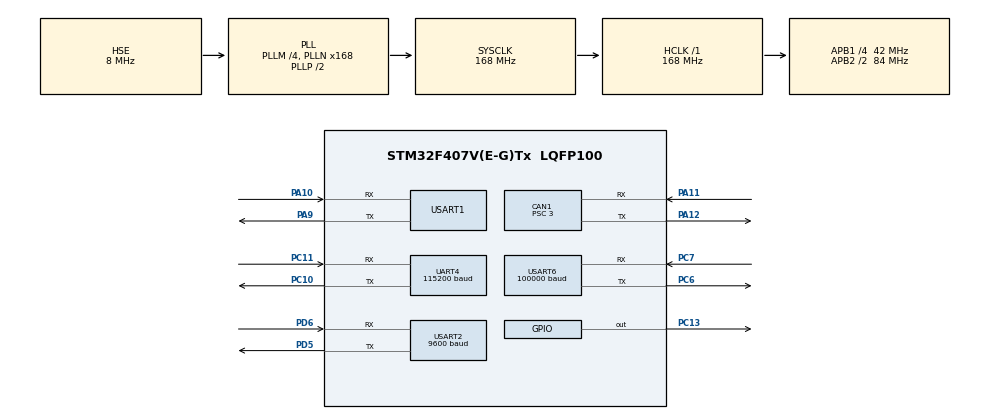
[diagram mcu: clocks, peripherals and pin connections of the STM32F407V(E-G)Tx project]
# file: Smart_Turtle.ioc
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CAN1.BS1=CAN_BS1_10TQ
CAN1.BS2=CAN_BS2_3TQ
CAN1.CalculateBaudRate=1000000
CAN1.CalculateTimeBit=1000
CAN1.CalculateTimeQuantum=71.42857142857143
CAN1.Prescaler=3
Dma.Request0=USART1_RX
Dma.Request1=USART1_TX
Dma.Request2=USART2_TX
Dma.Request3=USART2_RX
Dma.Request4=USART6_RX
Dma.Request5=USART6_TX
Dma.USART1_RX.0.Direction=DMA_PERIPH_TO_MEMORY
Dma.USART1_RX.0.FIFOMode=DMA_FIFOMODE_DISABLE
Dma.USART1_RX.0.Instance=DMA2_Stream2
Dma.USART1_RX.0.MemDataAlignment=DMA_MDATAALIGN_BYTE
Dma.USART1_RX.0.MemInc=DMA_MINC_ENABLE
Dma.USART1_RX.0.Mode=DMA_NORMAL
Dma.USART1_RX.0.PeriphDataAlignment=DMA_PDATAALIGN_BYTE
Dma.USART1_RX.0.PeriphInc=DMA_PINC_DISABLE
Dma.USART1_RX.0.Priority=DMA_PRIORITY_VERY_HIGH
Dma.USART1_TX.1.Direction=DMA_MEMORY_TO_PERIPH
Dma.USART1_TX.1.FIFOMode=DMA_FIFOMODE_DISABLE
Dma.USART1_TX.1.Instance=DMA2_Stream7
Dma.USART1_TX.1.MemDataAlignment=DMA_MDATAALIGN_BYTE
Dma.USART1_TX.1.MemInc=DMA_MINC_ENABLE
Dma.USART1_TX.1.Mode=DMA_NORMAL
Dma.USART1_TX.1.PeriphDataAlignment=DMA_PDATAALIGN_BYTE
Dma.USART1_TX.1.PeriphInc=DMA_PINC_DISABLE
Dma.USART1_TX.1.Priority=DMA_PRIORITY_VERY_HIGH
Dma.USART2_RX.3.Direction=DMA_PERIPH_TO_MEMORY
Dma.USART2_RX.3.FIFOMode=DMA_FIFOMODE_DISABLE
Dma.USART2_RX.3.Instance=DMA1_Stream5
Dma.USART2_RX.3.MemDataAlignment=DMA_MDATAALIGN_BYTE
Dma.USART2_RX.3.MemInc=DMA_MINC_ENABLE
Dma.USART2_RX.3.Mode=DMA_NORMAL
Dma.USART2_RX.3.PeriphDataAlignment=DMA_PDATAALIGN_BYTE
Dma.USART2_RX.3.PeriphInc=DMA_PINC_DISABLE
Dma.USART2_RX.3.Priority=DMA_PRIORITY_VERY_HIGH
Dma.USART2_TX.2.Direction=DMA_MEMORY_TO_PERIPH
Dma.USART2_TX.2.FIFOMode=DMA_FIFOMODE_DISABLE
Dma.USART2_TX.2.Instance=DMA1_Stream6
Dma.USART2_TX.2.MemDataAlignment=DMA_MDATAALIGN_BYTE
Dma.USART2_TX.2.MemInc=DMA_MINC_ENABLE
Dma.USART2_TX.2.Mode=DMA_NORMAL
Dma.USART2_TX.2.PeriphDataAlignment=DMA_PDATAALIGN_BYTE
Dma.USART2_TX.2.PeriphInc=DMA_PINC_DISABLE
Dma.USART2_TX.2.Priority=DMA_PRIORITY_VERY_HIGH
Dma.USART6_RX.4.Direction=DMA_PERIPH_TO_MEMORY
Dma.USART6_RX.4.FIFOMode=DMA_FIFOMODE_DISABLE
Dma.USART6_RX.4.Instance=DMA2_Stream1
Dma.USART6_RX.4.MemDataAlignment=DMA_MDATAALIGN_BYTE
Dma.USART6_RX.4.MemInc=DMA_MINC_ENABLE
Dma.USART6_RX.4.Mode=DMA_NORMAL
Dma.USART6_RX.4.PeriphDataAlignment=DMA_PDATAALIGN_BYTE
Dma.USART6_RX.4.PeriphInc=DMA_PINC_DISABLE
Dma.USART6_RX.4.Priority=DMA_PRIORITY_VERY_HIGH
Dma.USART6_TX.5.Direction=DMA_MEMORY_TO_PERIPH
Dma.USART6_TX.5.FIFOMode=DMA_FIFOMODE_DISABLE
Dma.USART6_TX.5.Instance=DMA2_Stream6
Dma.USART6_TX.5.MemDataAlignment=DMA_MDATAALIGN_BYTE
Dma.USART6_TX.5.MemInc=DMA_MINC_ENABLE
Dma.USART6_TX.5.Mode=DMA_NORMAL
Dma.USART6_TX.5.PeriphDataAlignment=DMA_PDATAALIGN_BYTE
Dma.USART6_TX.5.PeriphInc=DMA_PINC_DISABLE
Dma.USART6_TX.5.Priority=DMA_PRIORITY_MEDIUM
FREERTOS.INCLUDE_eTaskGetState=1
FREERTOS.INCLUDE_pcTaskGetTaskName=1
FREERTOS.INCLUDE_uxTaskGetStackHighWaterMark=1
FREERTOS.INCLUDE_vTaskCleanUpResources=1
FREERTOS.INCLUDE_vTaskDelayUntil=1
FREERTOS.INCLUDE_xQueueGetMutexHolder=1
FREERTOS.INCLUDE_xSemaphoreGetMutexHolder=1
FREERTOS.INCLUDE_xTaskAbortDelay=1
FREERTOS.INCLUDE_xTaskGetCurrentTaskHandle=1
FREERTOS.INCLUDE_xTaskGetHandle=1
FREERTOS.Tasks01=Chassis_TASK,1,512,Chassis_Task,As weak,NULL,Dynamic,NULL,NULL;Switch_TASK,0,128,Switch_Task,As weak,NULL,Dynamic,NULL,NULL;Auto_TASK,-1,512,Auto_Task,As weak,NULL,Dynamic,NULL,NULL
FREERTOS.configUSE_NEWLIB_REENTRANT=1
Mcu.Family=STM32F4
Mcu.Name=STM32F407V(E-G)Tx
Mcu.Package=LQFP100
NVIC.CAN1_RX0_IRQn=true\:5\:0\:true\:false\:true\:true\:true\:true\:true
NVIC.DMA1_Stream5_IRQn=true\:5\:0\:true\:false\:true\:true\:false\:true\:true
NVIC.DMA1_Stream6_IRQn=true\:5\:0\:true\:false\:true\:true\:false\:true\:true
NVIC.DMA2_Stream1_IRQn=true\:5\:0\:true\:false\:true\:true\:false\:true\:true
NVIC.DMA2_Stream2_IRQn=true\:5\:0\:true\:false\:true\:true\:false\:true\:true
NVIC.DMA2_Stream6_IRQn=true\:5\:0\:true\:false\:true\:true\:false\:true\:true
NVIC.DMA2_Stream7_IRQn=true\:5\:0\:true\:false\:true\:true\:false\:true\:true
NVIC.PriorityGroup=NVIC_PRIORITYGROUP_4
NVIC.TIM2_IRQn=true\:15\:0\:false\:false\:true\:false\:false\:true\:true
NVIC.TimeBase=TIM2_IRQn
NVIC.TimeBaseIP=TIM2
NVIC.UART4_IRQn=true\:5\:0\:true\:false\:true\:true\:true\:true\:true
NVIC.USART1_IRQn=true\:5\:0\:true\:false\:true\:true\:true\:true\:true
NVIC.USART2_IRQn=true\:5\:0\:true\:false\:true\:true\:true\:true\:true
NVIC.USART6_IRQn=true\:5\:0\:true\:false\:true\:true\:true\:true\:true
PA10.Mode=Asynchronous
PA10.Signal=USART1_RX
PA11.Mode=CAN_Activate
PA11.Signal=CAN1_RX
PA12.Mode=CAN_Activate
PA12.Signal=CAN1_TX
PA13.Mode=Serial_Wire
PA13.Signal=SYS_JTMS-SWDIO
PA14.Mode=Serial_Wire
PA14.Signal=SYS_JTCK-SWCLK
PA9.Mode=Asynchronous
PA9.Signal=USART1_TX
PC10.Mode=Asynchronous
PC10.Signal=UART4_TX
PC11.Mode=Asynchronous
PC11.Signal=UART4_RX
PC13-ANTI_TAMP.GPIO_PuPd=GPIO_PULLUP
PC13-ANTI_TAMP.PinState=GPIO_PIN_SET
PC13-ANTI_TAMP.Signal=GPIO_Output
PC6.Mode=Asynchronous
PC6.Signal=USART6_TX
PC7.Mode=Asynchronous
PC7.Signal=USART6_RX
PD5.Mode=Asynchronous
PD5.Signal=USART2_TX
PD6.Mode=Asynchronous
PD6.Signal=USART2_RX
PH0-OSC_IN.Mode=HSE-External-Oscillator
PH0-OSC_IN.Signal=RCC_OSC_IN
PH1-OSC_OUT.Mode=HSE-External-Oscillator
PH1-OSC_OUT.Signal=RCC_OSC_OUT
ProjectManager.HeapSize=0x200
ProjectManager.StackSize=0x400
ProjectManager.TargetToolchain=STM32CubeIDE
RCC.48MHZClocksFreq_Value=84000000
RCC.AHBFreq_Value=168000000
RCC.APB1CLKDivider=RCC_HCLK_DIV4
RCC.APB1Freq_Value=42000000
RCC.APB1TimFreq_Value=84000000
RCC.APB2CLKDivider=RCC_HCLK_DIV2
RCC.APB2Freq_Value=84000000
RCC.APB2TimFreq_Value=168000000
RCC.CortexFreq_Value=168000000
RCC.HCLKFreq_Value=168000000
RCC.HSE_VALUE=8000000
RCC.HSI_VALUE=16000000
RCC.LSE_VALUE=32768
RCC.PLLM=4
RCC.PLLN=168
RCC.PLLSourceVirtual=RCC_PLLSOURCE_HSE
RCC.SYSCLKFreq_VALUE=168000000
RCC.SYSCLKSource=RCC_SYSCLKSOURCE_PLLCLK
RCC.VCOOutputFreq_Value=336000000
UART4.BaudRate=115200
UART4.VirtualMode=Asynchronous
USART1.VirtualMode=VM_ASYNC
USART2.BaudRate=9600
USART2.VirtualMode=VM_ASYNC
USART6.BaudRate=100000
USART6.VirtualMode=VM_ASYNC
VP_FREERTOS_VS_CMSIS_V1.Mode=CMSIS_V1
VP_SYS_VS_tim2.Mode=TIM2
board=custom

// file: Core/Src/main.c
/* USER CODE BEGIN Header */
/**
  ******************************************************************************
  * @file           : main.c
  * @brief          : Main program body
  ******************************************************************************
  * @attention
  *
  * Copyright (c) 2022 STMicroelectronics.
  * All rights reserved.
  *
  * This software is licensed under terms that can be found in the LICENSE file
  * in the root directory of this software component.
  * If no LICENSE file comes with this software, it is provided AS-IS.
  *
  ******************************************************************************
  */
/* USER CODE END Header */
#include "main.h"
#include "cmsis_os.h"
#include "can.h"
#include "dma.h"
#include "usart.h"
#include "gpio.h"

/* USER CODE BEGIN Includes */
#include "remote_control.h"
/* USER CODE END Includes */

void SystemClock_Config(void);
void MX_FREERTOS_Init(void);

int main(void)
{

  /* MCU Configuration--------------------------------------------------------*/

  /* Reset of all peripherals, Initializes the Flash interface and the Systick. */
  HAL_Init();

  /* Configure the system clock */
  SystemClock_Config();

  /* Initialize all configured peripherals */
  MX_GPIO_Init();
  MX_DMA_Init();
  MX_CAN1_Init();
  MX_USART1_UART_Init();
  MX_UART4_Init();
  MX_USART2_UART_Init();
  MX_USART6_UART_Init();
  /* USER CODE BEGIN 2 */
  remote_control_init();
  /* USER CODE END 2 */

  /* Call init function for freertos objects (in freertos.c) */
  MX_FREERTOS_Init();

  /* Start scheduler */
  osKernelStart();

  /* We should never get here as control is now taken by the scheduler */
  /* Infinite loop */
  while (1)
  {

  }
}

void SystemClock_Config(void)
{
  RCC_OscInitTypeDef RCC_OscInitStruct = {0};
  RCC_ClkInitTypeDef RCC_ClkInitStruct = {0};

  /** Configure the main internal regulator output voltage
  */
  __HAL_RCC_PWR_CLK_ENABLE();
  __HAL_PWR_VOLTAGESCALING_CONFIG(PWR_REGULATOR_VOLTAGE_SCALE1);

  /** Initializes the RCC Oscillators according to the specified parameters
  * in the RCC_OscInitTypeDef structure.
  */
  RCC_OscInitStruct.OscillatorType = RCC_OSCILLATORTYPE_HSE;
  RCC_OscInitStruct.HSEState = RCC_HSE_ON;
  RCC_OscInitStruct.PLL.PLLState = RCC_PLL_ON;
  RCC_OscInitStruct.PLL.PLLSource = RCC_PLLSOURCE_HSE;
  RCC_OscInitStruct.PLL.PLLM = 4;
  RCC_OscInitStruct.PLL.PLLN = 168;
  RCC_OscInitStruct.PLL.PLLP = RCC_PLLP_DIV2;
  RCC_OscInitStruct.PLL.PLLQ = 4;
  if (HAL_RCC_OscConfig(&RCC_OscInitStruct) != HAL_OK)
  {
    Error_Handler();
  }

  /** Initializes the CPU, AHB and APB buses clocks
  */
  RCC_ClkInitStruct.ClockType = RCC_CLOCKTYPE_HCLK|RCC_CLOCKTYPE_SYSCLK
                              |RCC_CLOCKTYPE_PCLK1|RCC_CLOCKTYPE_PCLK2;
  RCC_ClkInitStruct.SYSCLKSource = RCC_SYSCLKSOURCE_PLLCLK;
  RCC_ClkInitStruct.AHBCLKDivider = RCC_SYSCLK_DIV1;
  RCC_ClkInitStruct.APB1CLKDivider = RCC_HCLK_DIV4;
  RCC_ClkInitStruct.APB2CLKDivider = RCC_HCLK_DIV2;

  if (HAL_RCC_ClockConfig(&RCC_ClkInitStruct, FLASH_LATENCY_5) != HAL_OK)
  {
    Error_Handler();
  }
}

void HAL_TIM_PeriodElapsedCallback(TIM_HandleTypeDef *htim)
{
  if (htim->Instance == TIM2) {
    HAL_IncTick();
  }
}

void Error_Handler(void)
{
  __disable_irq();
  while (1)
  {
  }
}

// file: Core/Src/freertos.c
/* USER CODE BEGIN Header */
/**
  ******************************************************************************
  * File Name          : freertos.c
  * Description        : Code for freertos applications
  ******************************************************************************
  * @attention
  *
  * Copyright (c) 2022 STMicroelectronics.
  * All rights reserved.
  *
  * This software is licensed under terms that can be found in the LICENSE file
  * in the root directory of this software component.
  * If no LICENSE file comes with this software, it is provided AS-IS.
  *
  ******************************************************************************
  */
/* USER CODE END Header */

#include "FreeRTOS.h"
#include "task.h"
#include "main.h"
#include "cmsis_os.h"

osThreadId Chassis_TASKHandle;
osThreadId Switch_TASKHandle;
osThreadId Auto_TASKHandle;

void Chassis_Task(void const * argument);
void Switch_Task(void const * argument);
void Auto_Task(void const * argument);

void MX_FREERTOS_Init(void); /* (MISRA C 2004 rule 8.1) */

/* GetIdleTaskMemory prototype (linked to static allocation support) */
void vApplicationGetIdleTaskMemory( StaticTask_t **ppxIdleTaskTCBBuffer, StackType_t **ppxIdleTaskStackBuffer, uint32_t *pulIdleTaskStackSize );

/* USER CODE BEGIN GET_IDLE_TASK_MEMORY */
static StaticTask_t xIdleTaskTCBBuffer;
static StackType_t xIdleStack[configMINIMAL_STACK_SIZE];

void vApplicationGetIdleTaskMemory( StaticTask_t **ppxIdleTaskTCBBuffer, StackType_t **ppxIdleTaskStackBuffer, uint32_t *pulIdleTaskStackSize )
{
  *ppxIdleTaskTCBBuffer = &xIdleTaskTCBBuffer;
  *ppxIdleTaskStackBuffer = &xIdleStack[0];
  *pulIdleTaskStackSize = configMINIMAL_STACK_SIZE;
  /* place for user code */
}
/* USER CODE END GET_IDLE_TASK_MEMORY */

void MX_FREERTOS_Init(void) {

  /* Create the thread(s) */
  /* definition and creation of Chassis_TASK */
  osThreadDef(Chassis_TASK, Chassis_Task, osPriorityAboveNormal, 0, 512);
  Chassis_TASKHandle = osThreadCreate(osThread(Chassis_TASK), NULL);

  /* definition and creation of Switch_TASK */
  osThreadDef(Switch_TASK, Switch_Task, osPriorityNormal, 0, 128);
  Switch_TASKHandle = osThreadCreate(osThread(Switch_TASK), NULL);

  /* definition and creation of Auto_TASK */
  osThreadDef(Auto_TASK, Auto_Task, osPriorityBelowNormal, 0, 512);
  Auto_TASKHandle = osThreadCreate(osThread(Auto_TASK), NULL);

}

__weak void Chassis_Task(void const * argument)
{
  for(;;)
  {
    osDelay(1);
  }
}

__weak void Switch_Task(void const * argument)
{
  for(;;)
  {
    osDelay(1);
  }
}

__weak void Auto_Task(void const * argument)
{
  for(;;)
  {
    osDelay(1);
  }
}
